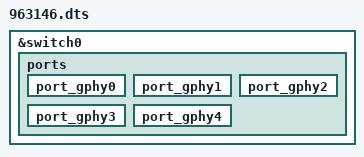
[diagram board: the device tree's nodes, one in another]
#include "63146.dtsi"
&switch0 {
	ports {
		port_gphy0 {
			status = "okay";
		};

		port_gphy1 {
			status = "okay";
		};

		port_gphy2 {
			status = "okay";
		};

		port_gphy3 {
			status = "okay";
		};

		port_gphy4 {
			status = "okay";
		};

/* FIXME
		port_rgmii {
			status = "okay";
		};
*/
	};
};

